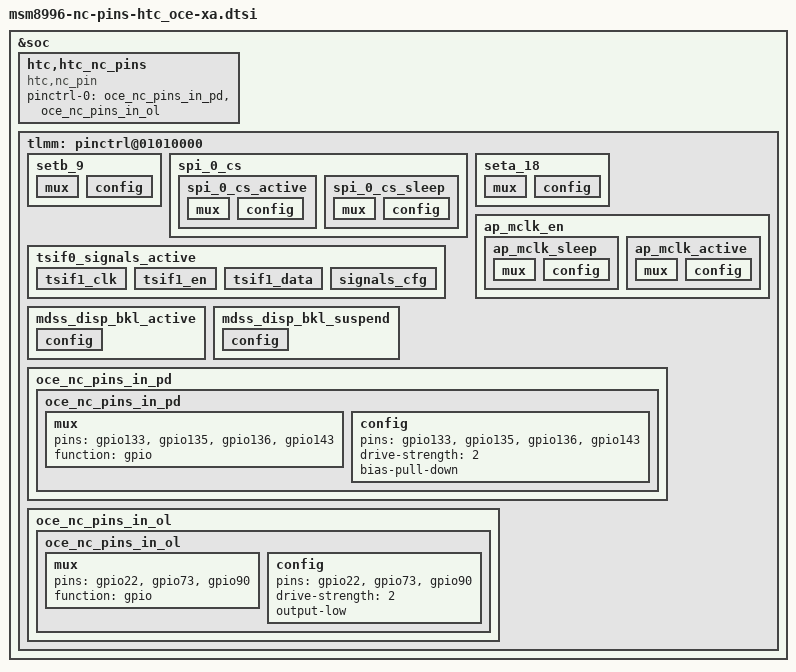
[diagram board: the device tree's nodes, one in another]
/* Copyright (c) 2016, The Linux Foundation. All rights reserved.
 *
 * This program is free software; you can redistribute it and/or modify
 * it under the terms of the GNU General Public License version 2 and
 * only version 2 as published by the Free Software Foundation.
 *
 * This program is distributed in the hope that it will be useful,
 * but WITHOUT ANY WARRANTY; without even the implied warranty of
 * MERCHANTABILITY or FITNESS FOR A PARTICULAR PURPOSE.  See the
 * GNU General Public License for more details.
 */

&soc {
	htc,htc_nc_pins {
		compatible = "htc,nc_pin";

		pinctrl-names = "default";
		pinctrl-0 = <&oce_nc_pins_in_pd &oce_nc_pins_in_ol>;
	};
};

&tlmm {
	oce_nc_pins_in_pd {
		oce_nc_pins_in_pd: oce_nc_pins_in_pd {
			mux {
				pins = "gpio133", "gpio135", "gpio136", "gpio143";
				function = "gpio";
			};

			config {
				pins = "gpio133", "gpio135", "gpio136", "gpio143";
				drive-strength = <2>;		/* 2 mA */
				bias-pull-down;			/* PULL DOWN */
			};
		};
	};

	 oce_nc_pins_in_ol {
                oce_nc_pins_in_ol: oce_nc_pins_in_ol {
                        mux {
                                pins = "gpio22", "gpio73", "gpio90";
                                function = "gpio";
                        };

                        config {
                                pins = "gpio22", "gpio73", "gpio90";
                                drive-strength = <2>;           /* 2 mA */
                                output-low;                 /* output low */
                        };
                };
        };

};

&soc {
	tlmm: pinctrl@01010000 {
		/* gpio22 */
                setb_9: setb_9 {
                        mux {
				/delete-property/ pins;
                        };

                        config {
				/delete-property/ pins;
                        };
                };
		/* gpio90 */
                spi_0_cs {
                        spi_0_cs_active: spi_0_cs_active {
                                mux {
					/delete-property/ pins;
                                };

                                config {
					/delete-property/ pins;
                                };
                        };

                        spi_0_cs_sleep: spi_0_cs_sleep {
                                mux {
					/delete-property/ pins;
                                };

                                config {
					/delete-property/ pins;
                                };
                        };
                };

                seta_18: seta_18 {
                        mux {
				/delete-property/ pins;
                        };

                        config {
				/delete-property/ pins;
                        };
                };

		tsif0_signals_active: tsif0_signals_active {
                        tsif1_clk {
				/delete-property/ pins;
                        };
                        tsif1_en {
				/delete-property/ pins;
                        };
                        tsif1_data {
				/delete-property/ pins;
                        };
                        signals_cfg {
				/delete-property/ pins;
                        };
                };

		/* gpio133 */
		ap_mclk_en {
			ap_mclk_sleep: ap_mclk_sleep {
				mux {
					/delete-property/ pins;
				};

				config {
					/delete-property/ pins;
				};
			};
			ap_mclk_active: ap_mclk_active {
				mux {
					/delete-property/ pins;
				};

				config {
					/delete-property/ pins;
				};
			};
		};

		/* gpio135 */
		mdss_disp_bkl_active: mdss_disp_bkl_active {
			config {
				/delete-property/ pins;
			};
		};

		mdss_disp_bkl_suspend: mdss_disp_bkl_suspend {
			config {
				/delete-property/ pins;
			};
		};

		/* gpio136 */
		/* gpio143 */
	};
};
